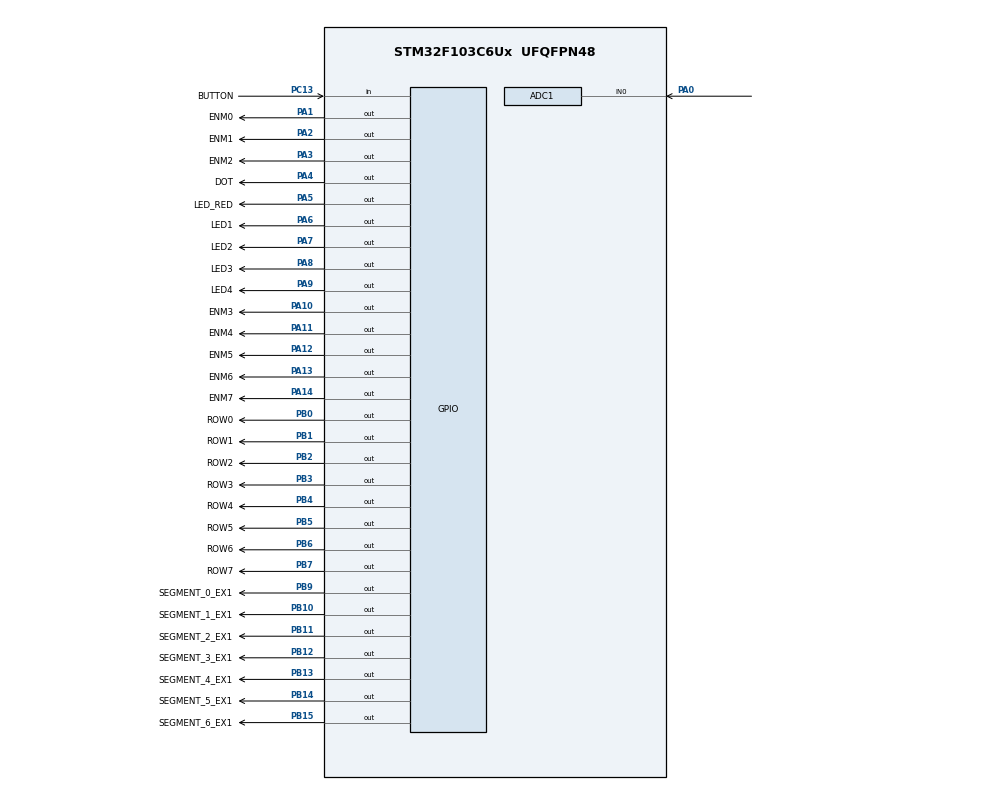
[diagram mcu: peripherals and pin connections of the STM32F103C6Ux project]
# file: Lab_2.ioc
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ADC1.Channel-0\#ChannelRegularConversion=ADC_CHANNEL_0
ADC1.ContinuousConvMode=ENABLE
ADC1.NbrOfConversionFlag=1
ADC1.Rank-0\#ChannelRegularConversion=1
ADC1.SamplingTime-0\#ChannelRegularConversion=ADC_SAMPLETIME_1CYCLE_5
ADC1.master=1
Mcu.Family=STM32F1
Mcu.Name=STM32F103C6Ux
Mcu.Package=UFQFPN48
NVIC.PriorityGroup=NVIC_PRIORITYGROUP_4
NVIC.TIM2_IRQn=true\:0\:0\:false\:false\:true\:true\:true
PA0-WKUP.Signal=ADCx_IN0
PA1.GPIO_Label=ENM0
PA1.Signal=GPIO_Output
PA10.GPIO_Label=ENM3
PA10.Signal=GPIO_Output
PA11.GPIO_Label=ENM4
PA11.Signal=GPIO_Output
PA12.GPIO_Label=ENM5
PA12.Signal=GPIO_Output
PA13.GPIO_Label=ENM6
PA13.Signal=GPIO_Output
PA14.GPIO_Label=ENM7
PA14.Signal=GPIO_Output
PA2.GPIO_Label=ENM1
PA2.Signal=GPIO_Output
PA3.GPIO_Label=ENM2
PA3.Signal=GPIO_Output
PA4.GPIO_Label=DOT
PA4.Signal=GPIO_Output
PA5.GPIO_Label=LED_RED
PA5.Signal=GPIO_Output
PA6.GPIO_Label=LED1
PA6.Signal=GPIO_Output
PA7.GPIO_Label=LED2
PA7.Signal=GPIO_Output
PA8.GPIO_Label=LED3
PA8.Signal=GPIO_Output
PA9.GPIO_Label=LED4
PA9.Signal=GPIO_Output
PB0.GPIO_Label=ROW0
PB0.Signal=GPIO_Output
PB1.GPIO_Label=ROW1
PB1.Signal=GPIO_Output
PB10.GPIO_Label=SEGMENT_1_EX1
PB10.Signal=GPIO_Output
PB11.GPIO_Label=SEGMENT_2_EX1
PB11.Signal=GPIO_Output
PB12.GPIO_Label=SEGMENT_3_EX1
PB12.Signal=GPIO_Output
PB13.GPIO_Label=SEGMENT_4_EX1
PB13.Signal=GPIO_Output
PB14.GPIO_Label=SEGMENT_5_EX1
PB14.Signal=GPIO_Output
PB15.GPIO_Label=SEGMENT_6_EX1
PB15.Signal=GPIO_Output
PB2.GPIO_Label=ROW2
PB2.Signal=GPIO_Output
PB3.GPIO_Label=ROW3
PB3.Signal=GPIO_Output
PB4.GPIO_Label=ROW4
PB4.Signal=GPIO_Output
PB5.GPIO_Label=ROW5
PB5.Signal=GPIO_Output
PB6.GPIO_Label=ROW6
PB6.Signal=GPIO_Output
PB7.GPIO_Label=ROW7
PB7.Signal=GPIO_Output
PB9.GPIO_Label=SEGMENT_0_EX1
PB9.Signal=GPIO_Output
PC13-TAMPER-RTC.GPIO_Label=BUTTON
PC13-TAMPER-RTC.GPIO_PuPd=GPIO_PULLUP
PC13-TAMPER-RTC.Signal=GPIO_Input
ProjectManager.HeapSize=0x200
ProjectManager.StackSize=0x400
ProjectManager.TargetToolchain=STM32CubeIDE
RCC.APB1Freq_Value=8000000
RCC.APB2Freq_Value=8000000
SH.ADCx_IN0.0=ADC1_IN0,IN0
TIM2.Period=9
TIM2.Prescaler=7999
VP_SYS_VS_ND.Mode=No_Debug
VP_TIM2_VS_ClockSourceINT.Mode=Internal
board=custom

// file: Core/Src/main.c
/* USER CODE BEGIN Header */
/**
  ******************************************************************************
  * @file           : main.c
  * @brief          : Main program body
  ******************************************************************************
  * @attention
  *
  * <h2><center>&copy; Copyright (c) 2024 STMicroelectronics.
  * All rights reserved.</center></h2>
  *
  * This software component is licensed by ST under BSD 3-Clause license,
  * the "License"; You may not use this file except in compliance with the
  * License. You may obtain a copy of the License at:
  *                        opensource.org/licenses/BSD-3-Clause
  *
  ******************************************************************************
  */
/* USER CODE END Header */
#include <Lab_2_Ex_5-6-7-8.h>
#include "main.h"

/* USER CODE BEGIN Includes */
#include "software_timer.h"
//#include "button.h"
//#include "Lab_2_Ex_1.h"
//#include "Lab_2_Ex_2.h"
//#include "Lab_2_Ex_3.h"
//#include "Lab_2_Ex_4.h"
//#include "Lab_2_Ex_9.h"
//#include "Lab_2_Ex_10.h"
/* USER CODE END Includes */

ADC_HandleTypeDef hadc1;

TIM_HandleTypeDef htim2;

void SystemClock_Config(void);
static void MX_TIM2_Init(void);
static void MX_GPIO_Init(void);
static void MX_ADC1_Init(void);

int main(void)
{

  /* MCU Configuration--------------------------------------------------------*/

  /* Reset of all peripherals, Initializes the Flash interface and the Systick. */
  HAL_Init();

  /* Configure the system clock */
  SystemClock_Config();

  /* Initialize all configured peripherals */
  MX_TIM2_Init();
  MX_GPIO_Init();
  MX_ADC1_Init();
  /* USER CODE BEGIN 2 */
  HAL_TIM_Base_Start_IT(&htim2);
  HAL_ADC_Start(&hadc1);
  /* USER CODE END 2 */

  /* Infinite loop */
  /* USER CODE BEGIN WHILE */
  //  Default
     setTimer0(0, 1000);
  // Bai_1: 1s
  // setTimer0(1, 1000);
  //  init_exercise1();
  // Bai_2: 1s
  // setTimer0(2, 1000);
  //  init_exercise2();
  // Bai_3: 1s
  // setTimer0(3, 1000);
  // init_exercise3();
  // Bai_4: 1s
  // setTimer0(4, 1000);
  // init_exercise4();
  // Bai_5-6-7-8: 1s
     setTimer0(5, 10);
     setTimer0(6, 10);
     init_exercise5();
//  setTimer0(7, 20);
//  init_exercise9();
//  setTimer0(8, 20);
//  init_exercise10();
  while (1)
    {
              /* USER CODE END WHILE */
          	if(timer_flag[0] == 1){
          		HAL_GPIO_TogglePin(LED_RED_GPIO_Port, LED_RED_Pin);
          		setTimer0(0, 1000);
          	}

  //        	if(timer0_flag[0] == 1){
  //        		exercise1_run();
  //        	  	setTimer0(500);
  //        	}

  //        	if(timer0_flag[1] == 1){
  //        	    exercise2_run();
  //        	    setTimer0(500);
  //        	}

  //        	if(timer0_flag[2] == 1){
  //        	    exercise3_run();
  //        	    setTimer0(1000);
  //        	}

//  	  	    if(timer0_flag[3] == 1){
//  	            exercise4_run();
//  	            setTimer0(1000);
//  	        }
//          	if(timer_flag[4] == 1){
//          	  	exercise5_run();
//          	  	setTimer0(4, 250);
//          	}
          	if(timer_flag[5] == 1){
          		updateLed();
          	  	setTimer0(5, 250);
          	}

  	  	    if(timer_flag[6] == 1){
  				exercise5_run();
  				setTimer0(6, 1000);
  	  	    }
//	  	  	  if(timer_flag[7] == 1){
//	  	  		  exercise9_run();
//	  	  		  setTimer0(7, 20);
//	  	  	  }
//			  if(timer_flag[8] == 1){
//			  	  exercise10_run();
//			  	  setTimer0(8, 20);
//			  }

          //	 if(button1_flag == 1){
          //	 	 HAL_GPIO_TogglePin(LED_YELLOW_GPIO_Port, LED_YELLOW_Pin);
          //	 	 button1_flag = 0;
          //	 }
       }
}

void SystemClock_Config(void)
{
  RCC_OscInitTypeDef RCC_OscInitStruct = {0};
  RCC_ClkInitTypeDef RCC_ClkInitStruct = {0};
  RCC_PeriphCLKInitTypeDef PeriphClkInit = {0};

  /** Initializes the RCC Oscillators according to the specified parameters
  * in the RCC_OscInitTypeDef structure.
  */
  RCC_OscInitStruct.OscillatorType = RCC_OSCILLATORTYPE_HSI;
  RCC_OscInitStruct.HSIState = RCC_HSI_ON;
  RCC_OscInitStruct.HSICalibrationValue = RCC_HSICALIBRATION_DEFAULT;
  RCC_OscInitStruct.PLL.PLLState = RCC_PLL_NONE;
  if (HAL_RCC_OscConfig(&RCC_OscInitStruct) != HAL_OK)
  {
    Error_Handler();
  }
  /** Initializes the CPU, AHB and APB buses clocks
  */
  RCC_ClkInitStruct.ClockType = RCC_CLOCKTYPE_HCLK|RCC_CLOCKTYPE_SYSCLK
                              |RCC_CLOCKTYPE_PCLK1|RCC_CLOCKTYPE_PCLK2;
  RCC_ClkInitStruct.SYSCLKSource = RCC_SYSCLKSOURCE_HSI;
  RCC_ClkInitStruct.AHBCLKDivider = RCC_SYSCLK_DIV1;
  RCC_ClkInitStruct.APB1CLKDivider = RCC_HCLK_DIV1;
  RCC_ClkInitStruct.APB2CLKDivider = RCC_HCLK_DIV1;

  if (HAL_RCC_ClockConfig(&RCC_ClkInitStruct, FLASH_LATENCY_0) != HAL_OK)
  {
    Error_Handler();
  }
  PeriphClkInit.PeriphClockSelection = RCC_PERIPHCLK_ADC;
  PeriphClkInit.AdcClockSelection = RCC_ADCPCLK2_DIV2;
  if (HAL_RCCEx_PeriphCLKConfig(&PeriphClkInit) != HAL_OK)
  {
    Error_Handler();
  }
}

static void MX_ADC1_Init(void)
{

  ADC_ChannelConfTypeDef sConfig = {0};

  /** Common config
  */
  hadc1.Instance = ADC1;
  hadc1.Init.ScanConvMode = ADC_SCAN_DISABLE;
  hadc1.Init.ContinuousConvMode = ENABLE;
  hadc1.Init.DiscontinuousConvMode = DISABLE;
  hadc1.Init.ExternalTrigConv = ADC_SOFTWARE_START;
  hadc1.Init.DataAlign = ADC_DATAALIGN_RIGHT;
  hadc1.Init.NbrOfConversion = 1;
  if (HAL_ADC_Init(&hadc1) != HAL_OK)
  {
    Error_Handler();
  }
  /** Configure Regular Channel
  */
  sConfig.Channel = ADC_CHANNEL_0;
  sConfig.Rank = ADC_REGULAR_RANK_1;
  sConfig.SamplingTime = ADC_SAMPLETIME_1CYCLE_5;
  if (HAL_ADC_ConfigChannel(&hadc1, &sConfig) != HAL_OK)
  {
    Error_Handler();
  }

}

static void MX_TIM2_Init(void)
{

  TIM_ClockConfigTypeDef sClockSourceConfig = {0};
  TIM_MasterConfigTypeDef sMasterConfig = {0};

  htim2.Instance = TIM2;
  htim2.Init.Prescaler = 7999;
  htim2.Init.CounterMode = TIM_COUNTERMODE_UP;
  htim2.Init.Period = 9;
  htim2.Init.ClockDivision = TIM_CLOCKDIVISION_DIV1;
  htim2.Init.AutoReloadPreload = TIM_AUTORELOAD_PRELOAD_DISABLE;
  if (HAL_TIM_Base_Init(&htim2) != HAL_OK)
  {
    Error_Handler();
  }
  sClockSourceConfig.ClockSource = TIM_CLOCKSOURCE_INTERNAL;
  if (HAL_TIM_ConfigClockSource(&htim2, &sClockSourceConfig) != HAL_OK)
  {
    Error_Handler();
  }
  sMasterConfig.MasterOutputTrigger = TIM_TRGO_RESET;
  sMasterConfig.MasterSlaveMode = TIM_MASTERSLAVEMODE_DISABLE;
  if (HAL_TIMEx_MasterConfigSynchronization(&htim2, &sMasterConfig) != HAL_OK)
  {
    Error_Handler();
  }

}

static void MX_GPIO_Init(void)
{
  GPIO_InitTypeDef GPIO_InitStruct = {0};

  /* GPIO Ports Clock Enable */
  __HAL_RCC_GPIOC_CLK_ENABLE();
  __HAL_RCC_GPIOA_CLK_ENABLE();
  __HAL_RCC_GPIOB_CLK_ENABLE();

  /*Configure GPIO pin Output Level */
  HAL_GPIO_WritePin(GPIOA, ENM0_Pin|ENM1_Pin|ENM2_Pin|DOT_Pin
                          |LED_RED_Pin|LED1_Pin|LED2_Pin|LED3_Pin
                          |LED4_Pin|ENM3_Pin|ENM4_Pin|ENM5_Pin
                          |ENM6_Pin|ENM7_Pin, GPIO_PIN_RESET);

  /*Configure GPIO pin Output Level */
  HAL_GPIO_WritePin(GPIOB, ROW0_Pin|ROW1_Pin|ROW2_Pin|SEGMENT_1_EX1_Pin
                          |SEGMENT_2_EX1_Pin|SEGMENT_3_EX1_Pin|SEGMENT_4_EX1_Pin|SEGMENT_5_EX1_Pin
                          |SEGMENT_6_EX1_Pin|ROW3_Pin|ROW4_Pin|ROW5_Pin
                          |ROW6_Pin|ROW7_Pin|SEGMENT_0_EX1_Pin, GPIO_PIN_RESET);

  /*Configure GPIO pin : BUTTON_Pin */
  GPIO_InitStruct.Pin = BUTTON_Pin;
  GPIO_InitStruct.Mode = GPIO_MODE_INPUT;
  GPIO_InitStruct.Pull = GPIO_PULLUP;
  HAL_GPIO_Init(BUTTON_GPIO_Port, &GPIO_InitStruct);

  /*Configure GPIO pins : ENM0_Pin ENM1_Pin ENM2_Pin DOT_Pin
                           LED_RED_Pin LED1_Pin LED2_Pin LED3_Pin
                           LED4_Pin ENM3_Pin ENM4_Pin ENM5_Pin
                           ENM6_Pin ENM7_Pin */
  GPIO_InitStruct.Pin = ENM0_Pin|ENM1_Pin|ENM2_Pin|DOT_Pin
                          |LED_RED_Pin|LED1_Pin|LED2_Pin|LED3_Pin
                          |LED4_Pin|ENM3_Pin|ENM4_Pin|ENM5_Pin
                          |ENM6_Pin|ENM7_Pin;
  GPIO_InitStruct.Mode = GPIO_MODE_OUTPUT_PP;
  GPIO_InitStruct.Pull = GPIO_NOPULL;
  GPIO_InitStruct.Speed = GPIO_SPEED_FREQ_LOW;
  HAL_GPIO_Init(GPIOA, &GPIO_InitStruct);

  /*Configure GPIO pins : ROW0_Pin ROW1_Pin ROW2_Pin SEGMENT_1_EX1_Pin
                           SEGMENT_2_EX1_Pin SEGMENT_3_EX1_Pin SEGMENT_4_EX1_Pin SEGMENT_5_EX1_Pin
                           SEGMENT_6_EX1_Pin ROW3_Pin ROW4_Pin ROW5_Pin
                           ROW6_Pin ROW7_Pin SEGMENT_0_EX1_Pin */
  GPIO_InitStruct.Pin = ROW0_Pin|ROW1_Pin|ROW2_Pin|SEGMENT_1_EX1_Pin
                          |SEGMENT_2_EX1_Pin|SEGMENT_3_EX1_Pin|SEGMENT_4_EX1_Pin|SEGMENT_5_EX1_Pin
                          |SEGMENT_6_EX1_Pin|ROW3_Pin|ROW4_Pin|ROW5_Pin
                          |ROW6_Pin|ROW7_Pin|SEGMENT_0_EX1_Pin;
  GPIO_InitStruct.Mode = GPIO_MODE_OUTPUT_PP;
  GPIO_InitStruct.Pull = GPIO_NOPULL;
  GPIO_InitStruct.Speed = GPIO_SPEED_FREQ_LOW;
  HAL_GPIO_Init(GPIOB, &GPIO_InitStruct);

}

/* USER CODE BEGIN 4 */
void HAL_TIM_PeriodElapsedCallback(TIM_HandleTypeDef *htim)
{
	timer_run();
//	getKeyInput();
}
/* USER CODE END 4 */

void Error_Handler(void)
{
  __disable_irq();
  while (1)
  {
  }
}

/************************ (C) COPYRIGHT STMicroelectronics *****END OF FILE****/
